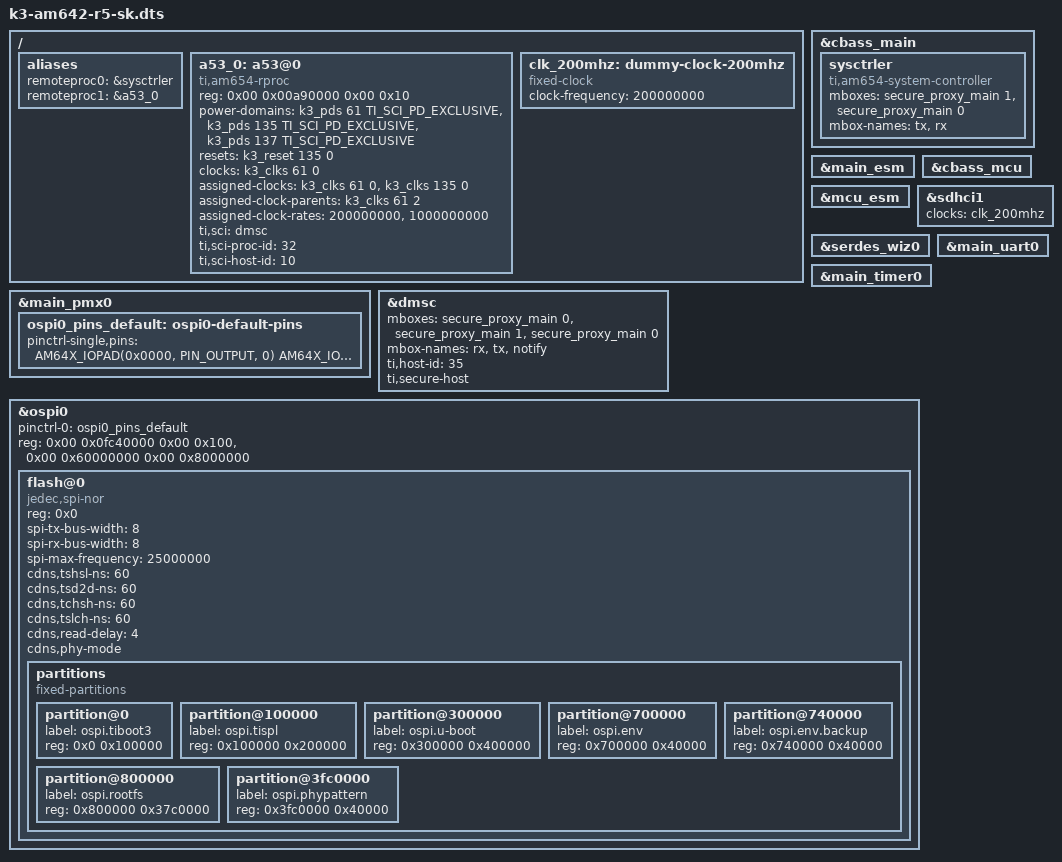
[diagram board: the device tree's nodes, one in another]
// SPDX-License-Identifier: GPL-2.0
/*
 * Copyright (C) 2021 Texas Instruments Incorporated - https://www.ti.com/
 */

#include "k3-am642-sk.dts"
#include "k3-am64-sk-lp4-1600MTs.dtsi"
#include "k3-am64-ddr.dtsi"

#include "k3-am642-sk-u-boot.dtsi"

/ {
	aliases {
		remoteproc0 = &sysctrler;
		remoteproc1 = &a53_0;
	};

	a53_0: a53@0 {
		compatible = "ti,am654-rproc";
		reg = <0x00 0x00a90000 0x00 0x10>;
		power-domains = <&k3_pds 61 TI_SCI_PD_EXCLUSIVE>,
				<&k3_pds 135 TI_SCI_PD_EXCLUSIVE>,
				<&k3_pds 137 TI_SCI_PD_EXCLUSIVE>;
		resets = <&k3_reset 135 0>;
		clocks = <&k3_clks 61 0>;
		assigned-clocks = <&k3_clks 61 0>, <&k3_clks 135 0>;
		assigned-clock-parents = <&k3_clks 61 2>;
		assigned-clock-rates = <200000000>, <1000000000>;
		ti,sci = <&dmsc>;
		ti,sci-proc-id = <32>;
		ti,sci-host-id = <10>;
		bootph-pre-ram;
	};

	clk_200mhz: dummy-clock-200mhz {
		compatible = "fixed-clock";
		#clock-cells = <0>;
		clock-frequency = <200000000>;
		bootph-pre-ram;
	};
};

&cbass_main {
	sysctrler: sysctrler {
		compatible = "ti,am654-system-controller";
		mboxes= <&secure_proxy_main 1>, <&secure_proxy_main 0>;
		mbox-names = "tx", "rx";
		bootph-pre-ram;
	};
};

&main_esm {
	bootph-pre-ram;
};

&cbass_mcu {
	bootph-pre-ram;
};

&mcu_esm {
	bootph-pre-ram;
};

&main_pmx0 {
	ospi0_pins_default: ospi0-default-pins {
		pinctrl-single,pins = <
		AM64X_IOPAD(0x0000, PIN_OUTPUT, 0) /* (N20) OSPI0_CLK */
		AM64X_IOPAD(0x002c, PIN_OUTPUT, 0) /* (L19) OSPI0_CSn0 */
		AM64X_IOPAD(0x000c, PIN_INPUT, 0) /* (M19) OSPI0_D0 */
		AM64X_IOPAD(0x0010, PIN_INPUT, 0) /* (M18) OSPI0_D1 */
		AM64X_IOPAD(0x0014, PIN_INPUT, 0) /* (M20) OSPI0_D2 */
		AM64X_IOPAD(0x0018, PIN_INPUT, 0) /* (M21) OSPI0_D3 */
		AM64X_IOPAD(0x001c, PIN_INPUT, 0) /* (P21) OSPI0_D4 */
		AM64X_IOPAD(0x0020, PIN_INPUT, 0) /* (P20) OSPI0_D5 */
		AM64X_IOPAD(0x0024, PIN_INPUT, 0) /* (N18) OSPI0_D6 */
		AM64X_IOPAD(0x0028, PIN_INPUT, 0) /* (M17) OSPI0_D7 */
		AM64X_IOPAD(0x0008, PIN_INPUT, 0) /* (N19) OSPI0_DQS */
		>;
	};
};

&dmsc {
	mboxes= <&secure_proxy_main 0>,
		<&secure_proxy_main 1>,
		<&secure_proxy_main 0>;
	mbox-names = "rx", "tx", "notify";
	ti,host-id = <35>;
	ti,secure-host;
};

&sdhci1 {
	clocks = <&clk_200mhz>;
	clock-names = "clk_xin";
};

&serdes_wiz0 {
	status = "okay";
};

/* UART is initialized before SYSFW is started
 * so we can't do any power-domain/clock operations.
 * Delete clock/power-domain properties to avoid
 * UART init failure
 */
&main_uart0 {
	/delete-property/ power-domains;
	/delete-property/ clocks;
	/delete-property/ clock-names;
};

/* timer init is called as part of rproc_start() while
 * starting System Firmware, so any clock/power-domain
 * operations will fail as SYSFW is not yet up and running.
 * Delete all clock/power-domain properties to avoid
 * timer init failure.
 * This is an always on timer at 20MHz.
 */
&main_timer0 {
	/delete-property/ clocks;
	/delete-property/ assigned-clocks;
	/delete-property/ assigned-clock-parents;
	/delete-property/ power-domains;
};

&ospi0 {
	pinctrl-names = "default";
	pinctrl-0 = <&ospi0_pins_default>;

	reg = <0x00 0x0fc40000 0x00 0x100>,
	      <0x00 0x60000000 0x00 0x8000000>;

	flash@0{
		compatible = "jedec,spi-nor";
		reg = <0x0>;
		spi-tx-bus-width = <8>;
		spi-rx-bus-width = <8>;
		spi-max-frequency = <25000000>;
		cdns,tshsl-ns = <60>;
		cdns,tsd2d-ns = <60>;
		cdns,tchsh-ns = <60>;
		cdns,tslch-ns = <60>;
		cdns,read-delay = <4>;
		cdns,phy-mode;
		#address-cells = <1>;
		#size-cells = <1>;

		partitions {
			compatible = "fixed-partitions";
			#address-cells = <1>;
			#size-cells = <1>;

			partition@0 {
				label = "ospi.tiboot3";
				reg = <0x0 0x100000>;
			};

			partition@100000 {
				label = "ospi.tispl";
				reg = <0x100000 0x200000>;
			};

			partition@300000 {
				label = "ospi.u-boot";
				reg = <0x300000 0x400000>;
			};

			partition@700000 {
				label = "ospi.env";
				reg = <0x700000 0x40000>;
			};

			partition@740000 {
				label = "ospi.env.backup";
				reg = <0x740000 0x40000>;
			};

			partition@800000 {
				label = "ospi.rootfs";
				reg = <0x800000 0x37c0000>;
			};

			partition@3fc0000 {
				label = "ospi.phypattern";
				reg = <0x3fc0000 0x40000>;
			};
		};
	};
};
